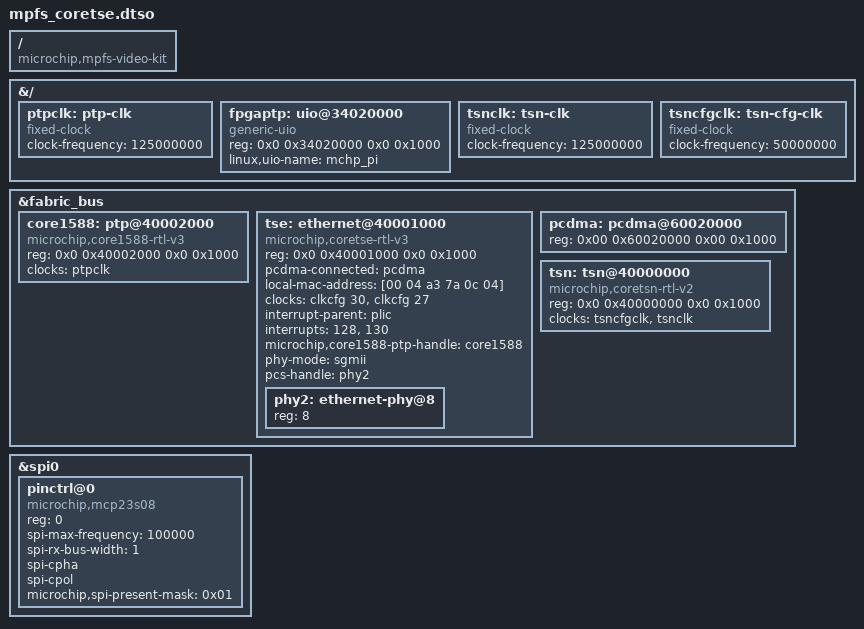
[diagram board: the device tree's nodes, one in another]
// SPDX-License-Identifier: (GPL-2.0+ OR MIT)
/*
 * Device Tree Overlay For CoreTSE(Triple Speed Ethernet) MAC.
 *
 * Copyright (C) 2025 Microchip Technology Inc. and its subsidiaries.
 *
 */

/dts-v1/;
/plugin/;

/ {
	compatible = "microchip,mpfs-video-kit","microchip,mpfs-sev-kit","microchip,mpfs";
};

&{/} {
	#address-cells = <2>;
	#size-cells = <2>;

	ptpclk: ptp-clk {
		compatible = "fixed-clock";
		#clock-cells = <0>;
		clock-frequency = <125000000>;
	};

	fpgaptp: uio@34020000 {
		compatible = "generic-uio";
		reg = <0x0 0x34020000 0x0 0x1000>;
		linux,uio-name = "mchp_pi";
		status = "okay";
	};

	tsnclk: tsn-clk {
		compatible = "fixed-clock";
		#clock-cells = <0>;
		clock-frequency = <125000000>;
       };

	tsncfgclk: tsn-cfg-clk {
		compatible = "fixed-clock";
		#clock-cells = <0>;
		clock-frequency = <50000000>;
       };
};

&fabric_bus {
	#address-cells = <2>;
	#size-cells = <2>;

	core1588: ptp@40002000 {
		compatible = "microchip,core1588-rtl-v3";
		reg = <0x0 0x40002000 0x0 0x1000>;
		clocks = <&ptpclk>;
		clock-names = "tsu";
		status = "okay";
	};

	tse: ethernet@40001000 {
		compatible = "microchip,coretse-rtl-v3";
		reg = <0x0 0x40001000 0x0 0x1000>;
		pcdma-connected = <&pcdma>;
		#address-cells = <1>;
		#size-cells = <0>;
		local-mac-address = [00 04 a3 7a 0c 04];
		clocks = <&clkcfg 30>, <&clkcfg 27>;
		clock-names = "pclk", "pcdma";
		interrupt-parent = <&plic>;
		interrupts = <128>, <130>;
		interrupt-names = "mm2s_pcdma", "s2mm_pcdma";
		microchip,core1588-ptp-handle = <&core1588>;
		status = "okay";

		phy-mode = "sgmii";
		pcs-handle = <&phy2>;

		phy2: ethernet-phy@8 {
				reg = <8>;
		};
	};

	pcdma: pcdma@60020000 {
		reg = <0x00 0x60020000 0x00 0x1000>;
	};

	tsn: tsn@40000000{
		compatible = "microchip,coretsn-rtl-v2";
		reg = <0x0 0x40000000 0x0 0x1000>;
		clocks = <&tsncfgclk>, <&tsnclk>;
		clock-names = "apb", "core";
	};
};

&spi0 {
	status = "okay";

	pinctrl@0 {
		compatible = "microchip,mcp23s08";
		reg = <0>;
		spi-max-frequency = <100000>;
		spi-rx-bus-width = <1>;
		spi-cpha;
		spi-cpol;
		microchip,spi-present-mask = <0x01>;
	};
};
